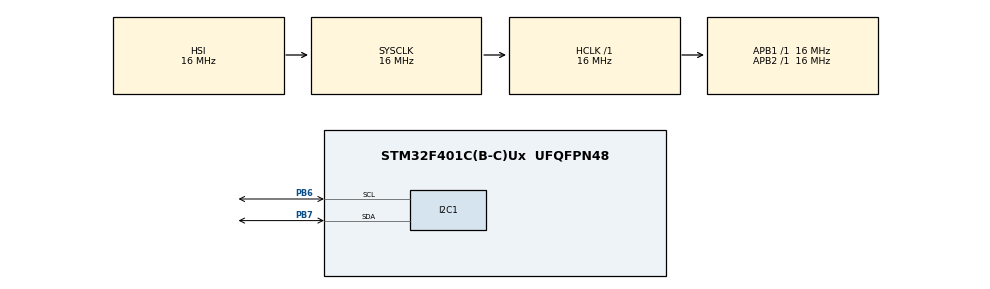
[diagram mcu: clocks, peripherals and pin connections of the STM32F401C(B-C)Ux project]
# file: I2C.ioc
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Mcu.Family=STM32F4
Mcu.Name=STM32F401C(B-C)Ux
Mcu.Package=UFQFPN48
NVIC.PriorityGroup=NVIC_PRIORITYGROUP_4
PB6.Mode=I2C
PB6.Signal=I2C1_SCL
PB7.Mode=I2C
PB7.Signal=I2C1_SDA
ProjectManager.HeapSize=0x200
ProjectManager.StackSize=0x400
ProjectManager.TargetToolchain=CMake
RCC.AHBFreq_Value=16000000
RCC.APB1Freq_Value=16000000
RCC.APB2Freq_Value=16000000
RCC.CortexFreq_Value=16000000
RCC.HSE_VALUE=25000000
RCC.HSI_VALUE=16000000
RCC.LSE_VALUE=32768
RCC.SYSCLKFreq_VALUE=16000000
RCC.VCOOutputFreq_Value=192000000
board=custom

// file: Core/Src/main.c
/* USER CODE BEGIN Header */
/**
  ******************************************************************************
  * @file           : main.c
  * @brief          : Main program body
  ******************************************************************************
  * @attention
  *
  * Copyright (c) 2026 STMicroelectronics.
  * All rights reserved.
  *
  * This software is licensed under terms that can be found in the LICENSE file
  * in the root directory of this software component.
  * If no LICENSE file comes with this software, it is provided AS-IS.
  *
  ******************************************************************************
  */
/* USER CODE END Header */
#include "main.h"
#include "lcd_i2c.h"

I2C_HandleTypeDef hi2c1;

void SystemClock_Config(void);
static void MX_GPIO_Init(void);
static void MX_I2C1_Init(void);
/* USER CODE BEGIN PFP */
static uint8_t LCD_FindAddress(I2C_HandleTypeDef *hi2c);

/* USER CODE END PFP */

/* USER CODE BEGIN 0 */
static uint8_t LCD_FindAddress(I2C_HandleTypeDef *hi2c)
{
  const uint8_t addresses[] = {
    0x20, 0x21, 0x22, 0x23, 0x24, 0x25, 0x26, 0x27,
    0x38, 0x39, 0x3A, 0x3B, 0x3C, 0x3D, 0x3E, 0x3F
  };

  for (uint32_t i = 0; i < sizeof(addresses); i++)
  {
    if (HAL_I2C_IsDeviceReady(hi2c, addresses[i] << 1, 3, 100) == HAL_OK)
      return addresses[i];
  }

  return 0;
}

uint8_t carita_feliz[8] =
{
    0b00000,
    0b01010,
    0b01010,
    0b00000,
    0b10001,
    0b10001,
    0b01110,
    0b00000
};

uint8_t estrella[8] =
{
    0b00100,
    0b10101,
    0b01110,
    0b11111,
    0b01110,
    0b10101,
    0b00100,
    0b00000
};

/* USER CODE END 0 */

int main(void)
{

  /* MCU Configuration--------------------------------------------------------*/

  /* Reset of all peripherals, Initializes the Flash interface and the Systick. */
  HAL_Init();

  /* Configure the system clock */
  SystemClock_Config();

  /* Initialize all configured peripherals */
  MX_GPIO_Init();
  MX_I2C1_Init();
  /* USER CODE BEGIN 2 */
  LCD_Init(&hi2c1);
  HAL_Init();

    SystemClock_Config();

    MX_GPIO_Init();
    MX_I2C1_Init();

    /* Inicializar LCD */
    LCD_Init(&hi2c1);

    LCD_CreateChar(0, carita_feliz);
    LCD_CreateChar(1, estrella);

    LCD_SetCursor(2, 0);
    LCD_WriteCustomChar(1);
    LCD_Print("  Hola mundo  ");
    LCD_WriteCustomChar(1);
    LCD_SetCursor(3, 11);
    LCD_WriteCustomChar(0);

    LCD_Print(" ");

  /* USER CODE END 2 */

  /* Infinite loop */
  while (1)
  {

  }
}

void SystemClock_Config(void)
{
  RCC_OscInitTypeDef RCC_OscInitStruct = {0};
  RCC_ClkInitTypeDef RCC_ClkInitStruct = {0};

  /** Configure the main internal regulator output voltage
  */
  __HAL_RCC_PWR_CLK_ENABLE();
  __HAL_PWR_VOLTAGESCALING_CONFIG(PWR_REGULATOR_VOLTAGE_SCALE2);

  /** Initializes the RCC Oscillators according to the specified parameters
  * in the RCC_OscInitTypeDef structure.
  */
  RCC_OscInitStruct.OscillatorType = RCC_OSCILLATORTYPE_HSI;
  RCC_OscInitStruct.HSIState = RCC_HSI_ON;
  RCC_OscInitStruct.HSICalibrationValue = RCC_HSICALIBRATION_DEFAULT;
  RCC_OscInitStruct.PLL.PLLState = RCC_PLL_NONE;
  if (HAL_RCC_OscConfig(&RCC_OscInitStruct) != HAL_OK)
  {
    Error_Handler();
  }

  /** Initializes the CPU, AHB and APB buses clocks
  */
  RCC_ClkInitStruct.ClockType = RCC_CLOCKTYPE_HCLK|RCC_CLOCKTYPE_SYSCLK
                              |RCC_CLOCKTYPE_PCLK1|RCC_CLOCKTYPE_PCLK2;
  RCC_ClkInitStruct.SYSCLKSource = RCC_SYSCLKSOURCE_HSI;
  RCC_ClkInitStruct.AHBCLKDivider = RCC_SYSCLK_DIV1;
  RCC_ClkInitStruct.APB1CLKDivider = RCC_HCLK_DIV1;
  RCC_ClkInitStruct.APB2CLKDivider = RCC_HCLK_DIV1;

  if (HAL_RCC_ClockConfig(&RCC_ClkInitStruct, FLASH_LATENCY_0) != HAL_OK)
  {
    Error_Handler();
  }
}

static void MX_I2C1_Init(void)
{

  hi2c1.Instance = I2C1;
  hi2c1.Init.ClockSpeed = 100000;
  hi2c1.Init.DutyCycle = I2C_DUTYCYCLE_2;
  hi2c1.Init.OwnAddress1 = 0;
  hi2c1.Init.AddressingMode = I2C_ADDRESSINGMODE_7BIT;
  hi2c1.Init.DualAddressMode = I2C_DUALADDRESS_DISABLE;
  hi2c1.Init.OwnAddress2 = 0;
  hi2c1.Init.GeneralCallMode = I2C_GENERALCALL_DISABLE;
  hi2c1.Init.NoStretchMode = I2C_NOSTRETCH_DISABLE;
  if (HAL_I2C_Init(&hi2c1) != HAL_OK)
  {
    Error_Handler();
  }

}

static void MX_GPIO_Init(void)
{

  /* GPIO Ports Clock Enable */
  __HAL_RCC_GPIOB_CLK_ENABLE();

}

void Error_Handler(void)
{
  __disable_irq();
  while (1)
  {
  }
}
